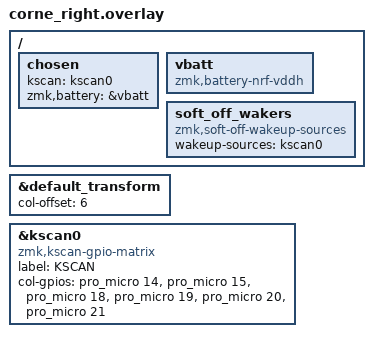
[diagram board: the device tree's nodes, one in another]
/*
 * Copyright (c) 2020 Pete Johanson
 *
 * SPDX-License-Identifier: MIT
 */

#include "corne.dtsi"

&default_transform {
	col-offset = <6>;
};

&kscan0 {
    label = "KSCAN";
    compatible = "zmk,kscan-gpio-matrix";
    col-gpios
        = <&pro_micro 14  GPIO_ACTIVE_HIGH>
        , <&pro_micro 15  GPIO_ACTIVE_HIGH>
        , <&pro_micro 18  GPIO_ACTIVE_HIGH>
        , <&pro_micro 19  GPIO_ACTIVE_HIGH>
        , <&pro_micro 20  GPIO_ACTIVE_HIGH>
        , <&pro_micro 21  GPIO_ACTIVE_HIGH>
        ;
};


/ {
    chosen {
      kscan = <&kscan0>;
      zmk,battery = &vbatt;
    };

    vbatt: vbatt {
        compatible = "zmk,battery-nrf-vddh";
    };
    // wakeup_scan: wakeup_scan {
    //     compatible = "zmk,kscan-gpio-direct";
    //     input-keys = <&soft_off_gpio_key>;
    //     wakeup-source;
    // };
    soft_off_wakers {
        compatible = "zmk,soft-off-wakeup-sources";
        wakeup-sources = <&kscan0>;
    };
};

// vim: set ft=dts :
